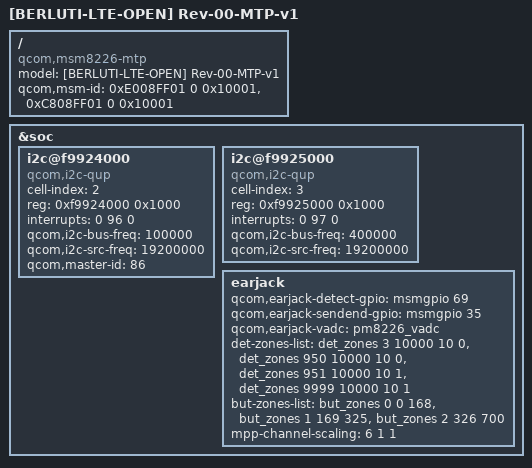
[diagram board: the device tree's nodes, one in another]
/* Copyright (c) 2013, The Linux Foundation. All rights reserved.
 *
 * This program is free software; you can redistribute it and/or modify
 * it under the terms of the GNU General Public License version 2 and
 * only version 2 as published by the Free Software Foundation.
 *
 * This program is distributed in the hope that it will be useful,
 * but WITHOUT ANY WARRANTY; without even the implied warranty of
 * MERCHANTABILITY or FITNESS FOR A PARTICULAR PURPOSE.  See the
 * GNU General Public License for more details.
 */

/* qcom,msm-id =<DT_INFO SS_BOARD_HARDWARE_REV QC_SOC_REVISION>
 * All these three fields are unsigned 32 bit integers
 * DT_INFO = [31:24] chip-id, [23:16] platform-id, [15:8] national code, [7:0] operator revision[ reserved]
 * SS_BOARD_HARDWARE_REV = Samsung specific hardware Revision
 * QC_SOC_REVISION = Qcomm SOC Version of MTP Board
 * Please refer to .../lk/platform/msm_shared/dev_tree.c also
 */
 
/dts-v1/;
/include/ "msm8926.dtsi"
/include/ "msm8926-sec-berlutilte-r00.dtsi"

/ {
	model = "[BERLUTI-LTE-OPEN] Rev-00-MTP-v1";
	compatible = "qcom,msm8226-mtp", "qcom,msm8226", "qcom,mtp";
	qcom,msm-id = <0xE008FF01 0 0x10001>,
			<0xC808FF01 0 0x10001>;
};

&soc {
	i2c@f9924000 { /* BLSP-1 QUP-2 */
		cell-index = <2>;
		compatible = "qcom,i2c-qup";
		reg = <0xf9924000 0x1000>;
		#address-cells = <1>;
		#size-cells = <0>;
		reg-names = "qup_phys_addr";
		interrupts = <0 96 0>;
		interrupt-names = "qup_err_intr";
		qcom,i2c-bus-freq = <100000>;
		qcom,i2c-src-freq = <19200000>;
		qcom,master-id = <86>;
	};

	 i2c@f9925000 { /* BLSP-1 QUP-3 */
                cell-index = <3>;
                compatible = "qcom,i2c-qup";
                reg = <0xf9925000 0x1000>;
                #address-cells = <1>;
                #size-cells = <0>;
                reg-names = "qup_phys_addr";
                interrupts = <0 97 0>;
                interrupt-names = "qup_err_intr";
                qcom,i2c-bus-freq = <400000>; /* 400 khz frequency needed for SEC_NFC */
                qcom,i2c-src-freq = <19200000>;
        };

	earjack {
                /*Override GPIO properties*/
                qcom,earjack-detect-gpio = <&msmgpio 69 0>;
                qcom,earjack-sendend-gpio = <&msmgpio 35 0>;
                qcom,earjack-vadc = <&pm8226_vadc>;
				det-zones-list = <&det_zones 3 10000 10 0>,
                             <&det_zones 950 10000 10 0>,
                             <&det_zones 951 10000 10 1>,
                             <&det_zones 9999 10000 10 1>;
				but-zones-list = <&but_zones 0 0 168>,
                             <&but_zones 1 169 325>,
                             <&but_zones 2 326 700>;
		mpp-channel-scaling = <6 1 1>;
        };
};
